# SYSTICK_356.0 register map
Vendor: Texas Instruments
Peripheral module from a debugger description file (folder MSP432).
Registers are 32-bit, read-write, no defined reset value unless marked. A register's access mark holds for its fields unless they carry their own. Offsets are as the file gives them; lines under a group give offsets from that group; [hi:lo] are bit positions; {n}, {i} and the like mark numbered series; 'fields as' and 'values as' point back to an identical list; <NAME> marks a mode.

## SYSTICK
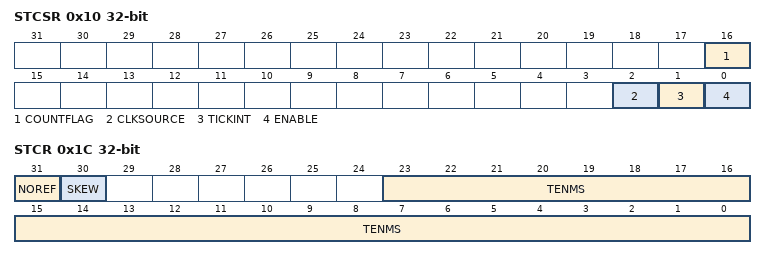
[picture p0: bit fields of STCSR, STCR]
0x10 STCSR access per field — SysTick Control and Status Register
  [16] COUNTFLAG ro — Returns 1 if timer counted to 0 since last time this was read. Clears on read by application of any part of the SysTick Control and Status Register. If read by the debugger using the DAP, this bit is cleared on read-only if the MasterType bit in the AHB-AP Control Register is set to 0. Otherwise, the COUNTFLAG bit is not changed by the debugger read.
  [2] CLKSOURCE ro — Clock source. If no reference clock is provided, it is held at 1 and so gives the same time as the core clock. The core clock must be at least 2.5 times faster than the reference clock. If it is not, the count values are Unpredictable.
    0=External reference clock; 1=Core clock
  [1] TICKINT rw
    0=Counting down to zero does not pend the SysTick handler. Software can use COUNTFLAG to determine if the SysTick handler has ever counted to zero.; 1=Counting down to zero pends the SysTick handler
  [0] ENABLE rw — Enable SysTick counter
    0=First (Counter disabled)
0x14 STRVR — SysTick Reload Value Register
  [23:0] RELOAD — Value to load into the SysTick Current Value Register when the counter reaches 0.
0x18 STCVR — SysTick Current Value Register
  [23:0] CURRENT — Current value at the time the register is accessed. No read-modify-write protection is provided, so change with care. Writing to it with any value clears the register to 0. Clearing this register also clears the COUNTFLAG bit of the SysTick Control and Status Register.
0x1C STCR ro — SysTick Calibration Value Register
  [31] NOREF — Reads as one. Indicates that no separate reference clock is provided.
  [30] SKEW — Reads as one. The calibration value is not exactly 10ms because of clock frequency. This could affect its suitability as a software real time clock.
  [23:0] TENMS — Reads as zero. Indicates calibration value is not known.
